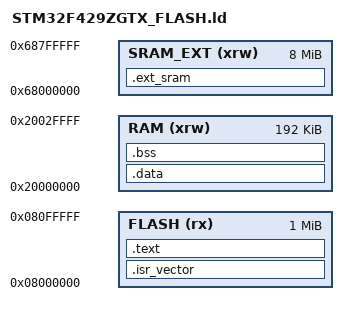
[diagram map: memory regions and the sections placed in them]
ENTRY(Reset_Handler)

MEMORY
{
  FLASH (rx)  : ORIGIN = 0x08000000, LENGTH = 1024K
  RAM   (xrw) : ORIGIN = 0x20000000, LENGTH = 192K
  SRAM_EXT (xrw) : ORIGIN = 0x68000000, LENGTH = 8192K
}

SECTIONS
{
  .isr_vector :
  {
    KEEP(*(.isr_vector))
  } > FLASH

  .text :
  {
    *(.text*)
    *(.rodata*)
    _etext = .;
  } > FLASH

  .data : AT(_etext)
  {
    _sdata = .;
    *(.data*)
    _edata = .;
  } > RAM

  .bss :
  {
    _sbss = .;
    *(.bss*)
    *(COMMON)
    _ebss = .;
  } > RAM

  .ext_sram (NOLOAD) :
  {
    *(.ext_sram*)
  } > SRAM_EXT
}
